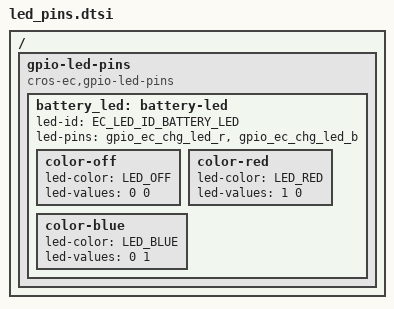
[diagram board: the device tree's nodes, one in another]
/* Copyright 2022 The ChromiumOS Authors
 * Use of this source code is governed by a BSD-style license that can be
 * found in the LICENSE file.
 */

/ {



gpio-led-pins {
		compatible = "cros-ec,gpio-led-pins";

		battery_led: battery-led {
			led-id = "EC_LED_ID_BATTERY_LED";
			led-pins = <&gpio_ec_chg_led_r &gpio_ec_chg_led_b>;

			color-off {
				led-color = "LED_OFF";
				led-values = <0 0>;
			};

			color-red {
				led-color = "LED_RED";
				led-values = <1 0>;
			};

			color-blue {
				led-color = "LED_BLUE";
				led-values = <0 1>;
			};
		};
	};
};
